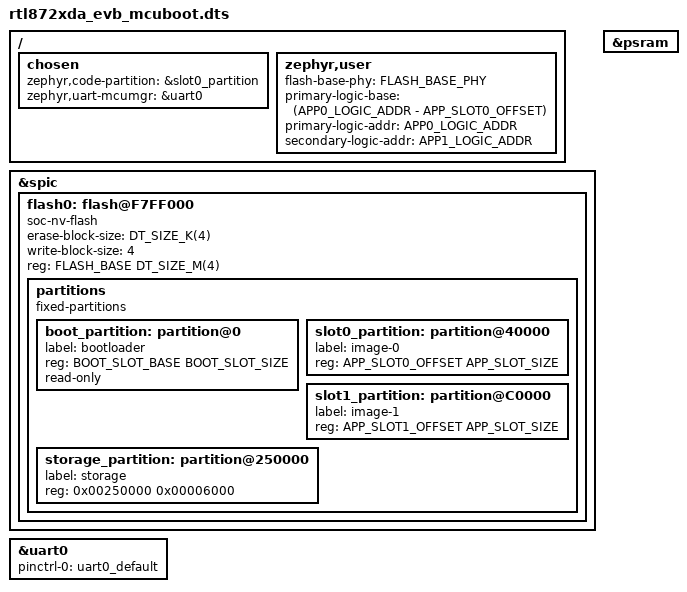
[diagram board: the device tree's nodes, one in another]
/*
 * Copyright (c) 2024 Realtek Semiconductor Corp.
 *
 * SPDX-License-Identifier: Apache-2.0
 */

#include "rtl872xda_evb_common.dts"

/**
 * BOOT refers to mcuboot bootloader, at smallest physical address
 * APP0 refers to km4, is primary image, at bigger physical address
 * APP1 refers to km0, is secondary image, at smaller physical address
 */

/* Parameters below are set based on the hardware/rom/custom by user */

#define FLASH_BASE_PHY 0x08000000
#define ROM_JUMP_ADDR 0x0F800020

/*WARNING: BETTER keep consistent with ameba_layout.ld::KM4_IMG2_XIP exclude header 0x20*/
#define APP0_LOGIC_ADDR 0x0E000000
/*WARNING: MUST keep consistent with ameba_layout.ld::KM0_IMG2_XIP exclude header 0x20*/
#define APP1_LOGIC_ADDR 0x0C000000

#define BOOT_SLOT_BASE 0x0
#define BOOT_SLOT_SIZE DT_SIZE_K(256) /* 0x40000 */

#define APP_SLOT_SIZE DT_SIZE_K(512) /* 0x80000 */

/* Parameters below are calculated automatically */

#define FLASH_BASE (ROM_JUMP_ADDR - 0x20 - 0x1000) /* 0x20: ameba header, 0x1000: manifest */

/* For merged km4 and km0 */
#define APP_SLOT0_OFFSET (BOOT_SLOT_BASE   + BOOT_SLOT_SIZE) /* 0x00040000, slot0_partition */
#define APP_SLOT1_OFFSET (APP_SLOT0_OFFSET + APP_SLOT_SIZE)  /* 0x000C0000, slot1_partition */

/{
	chosen {
		zephyr,code-partition = &slot0_partition;
		zephyr,uart-mcumgr = &uart0;
	};

	zephyr,user {
		flash-base-phy = <FLASH_BASE_PHY>;
		primary-logic-base = <(APP0_LOGIC_ADDR - APP_SLOT0_OFFSET)>;
		primary-logic-addr = <APP0_LOGIC_ADDR>;
		secondary-logic-addr = <APP1_LOGIC_ADDR>;
	};
};

/* 4MB flash */
/delete-node/ &flash0;
&spic {
	flash0: flash@F7FF000 {
		compatible = "soc-nv-flash";
		erase-block-size = <DT_SIZE_K(4)>;
		write-block-size = <4>;
		reg = <FLASH_BASE DT_SIZE_M(4)>;
		status = "okay";
		partitions {
			compatible = "fixed-partitions";
			#address-cells = <1>;
			#size-cells = <1>;

			boot_partition: partition@0 {
				label = "bootloader";
				reg = <BOOT_SLOT_BASE BOOT_SLOT_SIZE>;
				read-only;
			};

			slot0_partition: partition@40000 {
				label = "image-0";
				reg = <APP_SLOT0_OFFSET APP_SLOT_SIZE>;
			};

			slot1_partition: partition@C0000 {
				label = "image-1";
				reg = <APP_SLOT1_OFFSET APP_SLOT_SIZE>;
			};

			storage_partition: partition@250000 {
				label = "storage";
				reg = <0x00250000 0x00006000>;
			};
		};
	};
};

&uart0 {
	pinctrl-0 = <&uart0_default>;
	pinctrl-names = "default";
	status = "okay";
};

&spic {
	status = "okay";
};

&psram {
	status = "okay";
};
